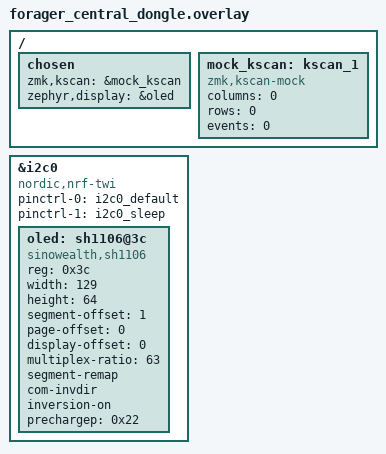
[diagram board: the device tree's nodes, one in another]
#include "forager.dtsi"

/ {
    chosen {
        zmk,kscan = &mock_kscan;
        zephyr,display = &oled;
    };

    mock_kscan: kscan_1 {
        compatible = "zmk,kscan-mock";
        columns = <0>;
        rows = <0>;
        events = <0>;
    };
};

/delete-node/ &kscan0;   // only required if the dongle uses a
                         // different board than the peripherals

&i2c0 {
	status = "okay";
	compatible = "nordic,nrf-twi";
    pinctrl-0 = <&i2c0_default>;
    pinctrl-1 = <&i2c0_sleep>;
	oled: sh1106@3c {
        compatible = "sinowealth,sh1106";
        reg = <0x3c>;
        width = <129>;
        height = <64>;
        segment-offset = <1>;
        page-offset = <0>;
        display-offset = <0>;
        multiplex-ratio = <63>;
        segment-remap;
        com-invdir;
        inversion-on;
        prechargep = <0x22>;
	};
};
/*
&xiao_i2c {
    status = "okay";

    oled: ssd1306@3c {
        compatible = "solomon,ssd1306fb";
        reg = <0x3c>;
        width = <128>;
        height = <64>;
        segment-offset = <0>;
        page-offset = <0>;
        display-offset = <0>;
        multiplex-ratio = <63>;
        segment-remap;
        com-invdir;
        inversion-on;
        prechargep = <0x22>;
    };
};
*/
